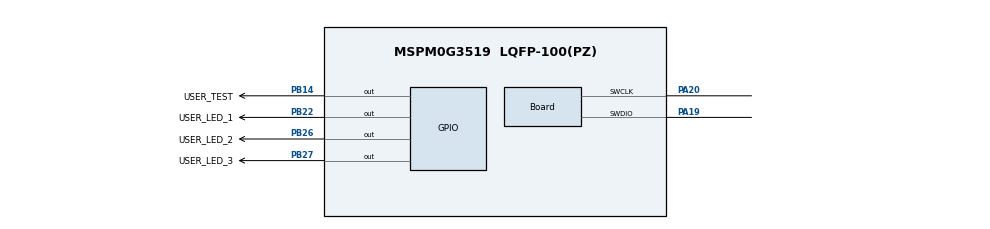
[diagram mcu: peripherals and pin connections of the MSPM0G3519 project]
//@cliArgs --device "MSPM0G351X" --package "LQFP-100(PZ)" --part "Default"
//@v2CliArgs --device "MSPM0G3519" --package "LQFP-100(PZ)"
// @cliArgs --board /ti/boards/LP_MSPM0G3519 --rtos nortos

/**
 * Import the modules used in this configuration.
 */
const GPIO   = scripting.addModule("/ti/driverlib/GPIO", {}, false);
const GPIO1  = GPIO.addInstance();
const SYSCTL = scripting.addModule("/ti/driverlib/SYSCTL");

/**
 * Write custom configuration values to the imported modules.
 */
GPIO1.$name                         = "GPIO_LEDS";
GPIO1.port                          = "PORTB";
GPIO1.associatedPins.create(4);
GPIO1.associatedPins[0].$name       = "USER_LED_1";
GPIO1.associatedPins[0].assignedPin = "22";
GPIO1.associatedPins[0].pin.$assign = "PB22";
GPIO1.associatedPins[1].$name       = "USER_LED_2";
GPIO1.associatedPins[1].assignedPin = "26";
GPIO1.associatedPins[1].pin.$assign = "PB26";
GPIO1.associatedPins[2].$name       = "USER_LED_3";
GPIO1.associatedPins[2].assignedPin = "27";
GPIO1.associatedPins[2].pin.$assign = "PB27";
GPIO1.associatedPins[3].$name       = "USER_TEST";
GPIO1.associatedPins[3].pin.$assign = "PB14";

const Board                       = scripting.addModule("/ti/driverlib/Board", {}, false);
Board.peripheral.$assign          = "DEBUGSS";
Board.peripheral.swclkPin.$assign = "PA20";
Board.peripheral.swdioPin.$assign = "PA19";

SYSCTL.forceDefaultClkConfig = true;
SYSCTL.clockTreeEn           = true;

const ProjectConfig              = scripting.addModule("/ti/project_config/ProjectConfig", {}, false);
ProjectConfig.migrationCondition = true;
